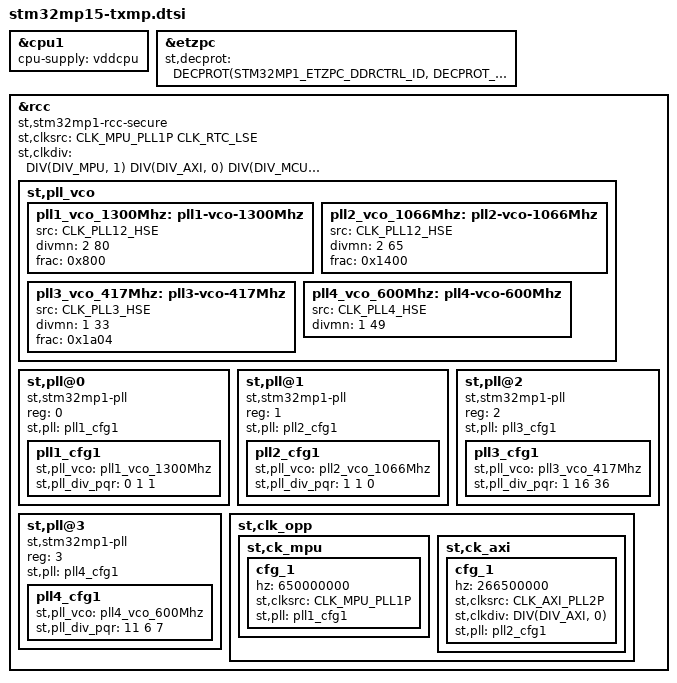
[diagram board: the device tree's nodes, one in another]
// SPDX-License-Identifier: (GPL-2.0-or-later OR BSD-3-Clause)
/*
 * Copyright (C) 2021 Lothar Waßmann <LW@KARO-electronics.de>
 * Copyright (C) 2024 Markus Bauer <MB@KARO-electronics.de>
 */

#include "stm32mp15-karo.dtsi"
#include "stm32mp15xxab-pinctrl.dtsi"

&cpu1 {
	cpu-supply = <&vddcpu>;
};

&etzpc {
	st,decprot = <
		/* "NS_R S_W" peripherals */
		DECPROT(STM32MP1_ETZPC_DDRCTRL_ID, DECPROT_NS_R_S_W, DECPROT_LOCK)
		DECPROT(STM32MP1_ETZPC_DDRPHYC_ID, DECPROT_NS_R_S_W, DECPROT_LOCK)
		/* "Non Secured" peripherals */
		DECPROT(STM32MP1_ETZPC_CRYP1_ID, DECPROT_NS_RW, DECPROT_UNLOCK)
		DECPROT(STM32MP1_ETZPC_DMA1_ID, DECPROT_NS_RW, DECPROT_UNLOCK)
		DECPROT(STM32MP1_ETZPC_DMAMUX_ID, DECPROT_NS_RW, DECPROT_UNLOCK)
		DECPROT(STM32MP1_ETZPC_ETH_ID, DECPROT_NS_RW, DECPROT_UNLOCK)
		DECPROT(STM32MP1_ETZPC_TT_FDCAN_ID, DECPROT_NS_RW, DECPROT_UNLOCK)
		DECPROT(STM32MP1_ETZPC_I2C1_ID, DECPROT_NS_RW, DECPROT_UNLOCK)
		DECPROT(STM32MP1_ETZPC_I2C2_ID, DECPROT_NS_RW, DECPROT_UNLOCK)
		DECPROT(STM32MP1_ETZPC_I2C3_ID, DECPROT_NS_RW, DECPROT_UNLOCK)
		DECPROT(STM32MP1_ETZPC_I2C4_ID, DECPROT_NS_RW, DECPROT_UNLOCK)
		DECPROT(STM32MP1_ETZPC_I2C5_ID, DECPROT_NS_RW, DECPROT_UNLOCK)
		DECPROT(STM32MP1_ETZPC_I2C6_ID, DECPROT_NS_RW, DECPROT_UNLOCK)
		DECPROT(STM32MP1_ETZPC_QSPI_ID, DECPROT_NS_RW, DECPROT_UNLOCK)
		DECPROT(STM32MP1_ETZPC_DLYBQ_ID, DECPROT_NS_RW, DECPROT_UNLOCK)
		DECPROT(STM32MP1_ETZPC_SAI1_ID, DECPROT_NS_RW, DECPROT_UNLOCK)
		DECPROT(STM32MP1_ETZPC_SAI2_ID, DECPROT_NS_RW, DECPROT_UNLOCK)
		DECPROT(STM32MP1_ETZPC_SAI3_ID, DECPROT_NS_RW, DECPROT_UNLOCK)
		DECPROT(STM32MP1_ETZPC_SPI1_ID, DECPROT_NS_RW, DECPROT_UNLOCK)
		DECPROT(STM32MP1_ETZPC_SPI2_ID, DECPROT_NS_RW, DECPROT_UNLOCK)
		DECPROT(STM32MP1_ETZPC_SPI3_ID, DECPROT_NS_RW, DECPROT_UNLOCK)
		DECPROT(STM32MP1_ETZPC_SPI4_ID, DECPROT_NS_RW, DECPROT_UNLOCK)
		DECPROT(STM32MP1_ETZPC_SPI6_ID, DECPROT_NS_RW, DECPROT_UNLOCK)
		DECPROT(STM32MP1_ETZPC_SDMMC3_ID, DECPROT_NS_RW, DECPROT_UNLOCK)
		DECPROT(STM32MP1_ETZPC_DLYBSD3_ID, DECPROT_NS_RW, DECPROT_UNLOCK)
		DECPROT(STM32MP1_ETZPC_TIM1_ID, DECPROT_NS_RW, DECPROT_UNLOCK)
		DECPROT(STM32MP1_ETZPC_UART4_ID, DECPROT_NS_RW, DECPROT_UNLOCK)
		DECPROT(STM32MP1_ETZPC_USART1_ID, DECPROT_NS_RW, DECPROT_UNLOCK)
		DECPROT(STM32MP1_ETZPC_USART2_ID, DECPROT_NS_RW, DECPROT_UNLOCK)
		DECPROT(STM32MP1_ETZPC_USART3_ID, DECPROT_NS_RW, DECPROT_UNLOCK)
		DECPROT(STM32MP1_ETZPC_UART5_ID, DECPROT_NS_RW, DECPROT_UNLOCK)
		DECPROT(STM32MP1_ETZPC_USART6_ID, DECPROT_NS_RW, DECPROT_UNLOCK)
		DECPROT(STM32MP1_ETZPC_UART7_ID, DECPROT_NS_RW, DECPROT_UNLOCK)
		DECPROT(STM32MP1_ETZPC_UART8_ID, DECPROT_NS_RW, DECPROT_UNLOCK)
		DECPROT(STM32MP1_ETZPC_OTG_ID, DECPROT_NS_RW, DECPROT_UNLOCK)
		/* "Secured" peripherals */
		DECPROT(STM32MP1_ETZPC_HASH1_ID, DECPROT_S_RW, DECPROT_UNLOCK)
		DECPROT(STM32MP1_ETZPC_RNG1_ID, DECPROT_S_RW, DECPROT_UNLOCK)
		DECPROT(STM32MP1_ETZPC_STGENC_ID, DECPROT_S_RW, DECPROT_UNLOCK)
		DECPROT(STM32MP1_ETZPC_BKPSRAM_ID, DECPROT_S_RW, DECPROT_LOCK)
		DECPROT(STM32MP1_ETZPC_IWDG1_ID, DECPROT_S_RW, DECPROT_LOCK)
		/* Internal RAM */
		DECPROT(STM32MP1_ETZPC_SRAM1_ID, DECPROT_NS_RW, DECPROT_UNLOCK)
		DECPROT(STM32MP1_ETZPC_SRAM2_ID, DECPROT_NS_RW, DECPROT_UNLOCK)
		DECPROT(STM32MP1_ETZPC_SRAM3_ID, DECPROT_NS_RW, DECPROT_UNLOCK)
		DECPROT(STM32MP1_ETZPC_RETRAM_ID, DECPROT_NS_RW, DECPROT_UNLOCK)
	>;
};

&rcc {
	compatible = "st,stm32mp1-rcc-secure";
	st,clksrc = <
		CLK_MPU_PLL1P
		/*
		 * OPTEE does not update downstream clock dividers when a clock
		 * parent is changed. So leave all clock sources at their reset
		 * defaults to prevent rogue clock rate changes due to
		 * reparenting clocks.
		 */
		CLK_RTC_LSE
/*
		CLK_MCU_PLL3P
		CLK_AXI_PLL2P
		CLK_MCO1_DISABLED
		CLK_MCO2_DISABLED
		CLK_CKPER_HSE
		CLK_FMC_ACLK
		CLK_QSPI_ACLK
		CLK_ETH_PLL4P
		CLK_SDMMC12_PLL4P
		CLK_DSI_DSIPLL
		CLK_STGEN_HSI
		CLK_USBPHY_HSE
		CLK_SPI2S1_PLL4P
		CLK_SPI2S23_PLL4P
		CLK_SPI45_PCLK2
		CLK_SPI6_PCLK5
		CLK_I2C46_PCLK5
		CLK_SDMMC3_HCLK2
		CLK_USBO_USBPHY
		CLK_ADC_PLL4R
		CLK_CEC_LSE
		CLK_I2C12_PCLK1
		CLK_I2C35_PCLK1
		CLK_UART1_PCLK5
		CLK_UART24_PCLK1
		CLK_UART35_PCLK1
		CLK_UART6_PCLK2
		CLK_UART78_PCLK1
		CLK_SPDIF_PLL4P
		CLK_FDCAN_HSE
		CLK_SAI1_PLL4Q
		CLK_SAI2_PLL4Q
		CLK_SAI3_PLL4Q
		CLK_SAI4_PLL4Q
		CLK_RNG1_CSI
		CLK_RNG2_CSI
		CLK_LPTIM1_PCLK1
		CLK_LPTIM23_PCLK3
		CLK_LPTIM45_PCLK3
*/
	>;
	st,clkdiv = <
		DIV(DIV_MPU, 1)
		DIV(DIV_AXI, 0)
		DIV(DIV_MCU, 0)
		DIV(DIV_APB1, 1)
		DIV(DIV_APB2, 1)
		DIV(DIV_APB3, 1)
		DIV(DIV_APB4, 1)
		DIV(DIV_APB5, 2)
		DIV(DIV_MCO1, 0)
		DIV(DIV_MCO2, 0)
	>;
	status = "okay";

	st,pll_vco {
		pll1_vco_1300Mhz: pll1-vco-1300Mhz {
			src = <CLK_PLL12_HSE>;
			divmn = <2 80>;
			frac = <0x800>;
		};

		pll2_vco_1066Mhz: pll2-vco-1066Mhz {
			src = <CLK_PLL12_HSE>;
			divmn = <2 65>;
			frac = <0x1400>;
		};

		pll3_vco_417Mhz: pll3-vco-417Mhz {
			src = <CLK_PLL3_HSE>;
			divmn = <1 33>;
			frac = <0x1a04>;
		};

		pll4_vco_600Mhz: pll4-vco-600Mhz {
			src = <CLK_PLL4_HSE>;
			divmn = <1 49>;
		};
	};

	st,pll@0 {
		reg = <0>;
		compatible = "st,stm32mp1-pll";
		st,pll = <&pll1_cfg1>;

		pll1_cfg1: pll1_cfg1 {
			st,pll_vco = <&pll1_vco_1300Mhz>;
			st,pll_div_pqr = <0 1 1>;
		};
	};

	st,pll@1 {
		reg = <1>;
		compatible = "st,stm32mp1-pll";
		st,pll = <&pll2_cfg1>;

		pll2_cfg1: pll2_cfg1 {
			st,pll_vco = <&pll2_vco_1066Mhz>;
			st,pll_div_pqr = <1 1 0>;
		};
	};

	st,pll@2 {
		reg = <2>;
		compatible = "st,stm32mp1-pll";
		st,pll = <&pll3_cfg1>;

		pll3_cfg1: pll3_cfg1 {
			st,pll_vco = <&pll3_vco_417Mhz>;
			st,pll_div_pqr = <1 16 36>;
		};
	};

	st,pll@3 {
		reg = <3>;
		compatible = "st,stm32mp1-pll";
		st,pll = <&pll4_cfg1>;

		pll4_cfg1: pll4_cfg1 {
			st,pll_vco = <&pll4_vco_600Mhz>;
			st,pll_div_pqr = <11 6 7>;
		};
	};

	st,clk_opp {
		st,ck_mpu {
			cfg_1 {
				hz = <650000000>;
				st,clksrc = <CLK_MPU_PLL1P>;
				st,pll = <&pll1_cfg1>;
			};
		};

		st,ck_axi {
			cfg_1 {
				hz = <266500000>;
				st,clksrc = <CLK_AXI_PLL2P>;
				st,clkdiv = <DIV(DIV_AXI, 0)>;
				st,pll = <&pll2_cfg1>;
			};
		};
	};
};
